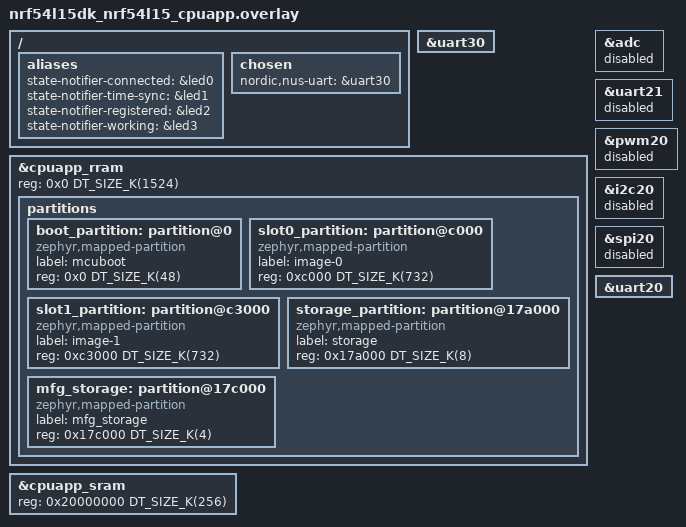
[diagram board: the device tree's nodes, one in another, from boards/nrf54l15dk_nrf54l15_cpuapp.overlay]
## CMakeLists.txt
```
#
# Copyright (c) 2023 Nordic Semiconductor ASA
#
# SPDX-License-Identifier: LicenseRef-Nordic-5-Clause
#

cmake_minimum_required(VERSION 3.20.0)

# Zephyr CMake project
find_package(Zephyr REQUIRED HINTS $ENV{ZEPHYR_BASE})
project(sidewalk_nus)

# Source files
target_include_directories(app PRIVATE include)
target_sources(app PRIVATE
src/main.c
src/sidewalk.c
src/sidewalk_events.c
)

target_sources_ifdef(CONFIG_SIDEWALK_FILE_TRANSFER app PRIVATE 
    src/sbdt/scratch_buffer.c
)
target_sources_ifdef(CONFIG_SIDEWALK_FILE_TRANSFER_DFU app PRIVATE
    src/sbdt/dfu_file_transfer.c
)

if(CONFIG_SID_END_DEVICE_SENSOR_MONITORING)
    target_sources(app PRIVATE
        src/sensor_monitoring/app_buttons.c
        src/sensor_monitoring/app_leds.c
        src/sensor_monitoring/app_sensor.c
        src/sensor_monitoring/app_tx.c
        src/sensor_monitoring/app_rx.c
        src/sensor_monitoring/app.c
    )
elseif(CONFIG_SID_END_DEVICE_DUT)
    target_sources(app PRIVATE
        src/cli/app.c
    )
else()
    target_sources(app PRIVATE
        src/hello/app.c
    )
endif()

target_sources_ifdef(CONFIG_SID_END_DEVICE_NUS_BRIDGE app PRIVATE
    src/nus_bridge/nus_bridge.c
)

if(CONFIG_SID_END_DEVICE_CLI)
    target_sources(app PRIVATE
        src/cli/app_dut.c
        src/cli/app_shell.c
    )
    target_sources_ifdef(CONFIG_SIDEWALK_FILE_TRANSFER_SHELL app PRIVATE
        src/cli/sbdt_shell.c
        src/cli/sbdt_shell_events.c
        src/cli/sbdt_shell_file_transfer.c
    )
    target_sources_ifdef(CONFIG_SIDEWALK_ON_DEV_CERT app PRIVATE 
        src/cli/sid_on_dev_cert_cli.c
    )
    target_sources_ifdef(CONFIG_SIDEWALK_LOCATION_SHELL app PRIVATE
        src/cli/location_shell.c
        src/cli/location_shell_events.c
    )
endif()

if(CONFIG_SIDEWALK_USE_PREBUILT_LIBRARIES)
    target_link_libraries(app PRIVATE sidewalk)
endif()
```

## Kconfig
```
#
# Copyright (c) 2022 Nordic Semiconductor ASA
#
# SPDX-License-Identifier: LicenseRef-Nordic-5-Clause
#

mainmenu "Sidewalk End Device nRF Connect Application"

choice SID_END_DEVICE
	prompt "Select application variant to run"
	default SID_END_DEVICE_HELLO
config SID_END_DEVICE_HELLO
	bool "Sidewalk hello world application"
config SID_END_DEVICE_SENSOR_MONITORING
	bool "Demo sensor monitoring application"
	imply SIDEWALK_DEMO_PARSER
	imply SENSOR
	imply TEMP_NRF5
config SID_END_DEVICE_DUT
	bool "Device under test application"
endchoice #SID_END_DEVICE

if SID_END_DEVICE_HELLO

config SID_END_DEVICE_ECHO_MSGS
	bool "Enable message echo feature"
	default y
	help
	  Echo received messages back to Sidewalk cloud.
	  Works with GET and SET messages types.

config SID_END_DEVICE_NUS_BRIDGE
	bool "Bridge Nordic UART Service to Sidewalk"
	select BT_NUS
	select SERIAL
	select UART_INTERRUPT_DRIVEN
	select RING_BUFFER
	help
	  Advertise the Nordic UART Service on the default BT identity next to Sidewalk.
	  The NUS peer can only send the commands !status, !mtu, !ping and !help,
	  answered over NUS; any other input is ignored and answered with the list of
	  commands. Sidewalk downlinks are notified to the NUS peer. Lines received on
	  the nordic,nus-uart UART are sent to the NUS peer, and all NUS traffic is
	  mirrored to that UART.

if SID_END_DEVICE_NUS_BRIDGE

config SID_END_DEVICE_NUS_BLE_NAME
	string "NUS advertising name"
	default "Sidewalk_NUS"

config SID_END_DEVICE_NUS_UART_LINE_MAX
	int "Max length of a UART line sent over NUS"
	default 128

endif # SID_END_DEVICE_NUS_BRIDGE

endif #SID_END_DEVICE_HELLO

# One more connection and advertising set for NUS. The Sidewalk add-on sets the
# same symbols, but defaults from the application Kconfig take precedence.
config BT_MAX_CONN
	default 3 if SID_END_DEVICE_NUS_BRIDGE && SIDEWALK_DFU
	default 2 if SID_END_DEVICE_NUS_BRIDGE

config BT_EXT_ADV_MAX_ADV_SET
	default 3 if SID_END_DEVICE_NUS_BRIDGE && SIDEWALK_DFU
	default 2 if SID_END_DEVICE_NUS_BRIDGE

if SID_END_DEVICE_SENSOR_MONITORING

rsource "Kconfig.sensor_monitoring"

endif #SID_END_DEVICE_SENSOR_MONITORING

config SID_END_DEVICE_CLI
	bool "Sidewalk CLI (DUT)"
	imply SHELL
	help
	  Enables Sidewalk command line interface.
	  The interface commands are compatible with former dut sample.

if SID_END_DEVICE_CLI

config SHELL_CMD_BUFF_SIZE
	default 1024

config SHELL_STACK_SIZE
	default 8192

config SHELL_BACKEND_SERIAL_TX_RING_BUFFER_SIZE
	default 128

config SHELL_BACKEND_SERIAL_RX_RING_BUFFER_SIZE
	default 1024

config SID_END_DEVICE_CLI_ALIVE_MARKER
	bool "Alive marker"
	help
	    Enable alive marker that periodically prints "alive" message to log.
	    Useful to verify that application is running and not stuck.

endif # SID_END_DEVICE_CLI

config SID_END_DEVICE_AUTO_START
	default y
	bool "Automatic Sidewalk initialization and start"

config SID_END_DEVICE_AUTO_CONN_REQ
	default y
	bool "Automatic connection request before message send"

config SID_END_DEVICE_PERSISTENT_LINK_MASK
	bool "Persistent link mask"
	help
	  The Sidewalk link mask persists after a device reset
	  but defaults after a factory reset.
	  This could affect the flash lifespan.

choice SID_END_DEVICE_LINK_MASK
	prompt "Physical link type"
	default SID_END_DEVICE_LINK_MASK_FSK if SIDEWALK_LINK_MASK_FSK
	default SID_END_DEVICE_LINK_MASK_LORA if SIDEWALK_LINK_MASK_LORA
	default SID_END_DEVICE_LINK_MASK_BLE if SIDEWALK_LINK_MASK_BLE
	default SID_END_DEVICE_LINK_MASK_BLE
	help
	  Choose the default physical link type for Sidewalk connection.

config SID_END_DEVICE_LINK_MASK_BLE
	bool "Bluetooth Low Energy link"

config SID_END_DEVICE_LINK_MASK_FSK
	bool "Sub-GHz link for FSK"

config SID_END_DEVICE_LINK_MASK_LORA
	bool "Sub-GHz link for LORA"

endchoice # SID_END_DEVICE_LINK_MASK

config SID_END_DEVICE_EVENT_HEAP_SIZE
	int "Heap for Sidewalk event contexts"
	default 2048

config SIDEWALK_FILE_TRANSFER
	select EXPERIMENTAL
	bool "Sidewalk file transfer [EXPERIMENTAL]"
	help
	  Add support for Sidewalk Bulk Data Transfer (SBDT)
	  in application.

if SIDEWALK_FILE_TRANSFER

config SIDEWALK_FILE_TRANSFER_HEAP_SIZE
	int "Sidewalk file transfer heap size"
	default 10240
	help
	    Heap size in bytes to be allocated
	    for Sidewalk Bulk Data Transfer (SBDT).

choice SIDEWALK_FILE_TRANSFER_IMPL
	prompt "Select which implementation of SBDT to use"
	default SIDEWALK_FILE_TRANSFER_DFU

config SIDEWALK_FILE_TRANSFER_DFU
	bool "Sidewalk file transfer and dfu"
	imply SIDEWALK_DFU_IMG_UTILS
	imply DFU_MULTI_IMAGE
	imply DFU_TARGET
	imply DFU_TARGET_MCUBOOT
	imply STREAM_FLASH
	imply STREAM_FLASH_ERASE
	help
	    Save received data to flash. Expect CBOR manifest.
	    Automatically reset device after file transfer.

config SIDEWALK_FILE_TRANSFER_SHELL
	bool "SBDT cli backend for file transfer"
	imply SHELL
	help
	    Use shell commands to control file transfer.
	    This implementation does not save received data,
	    but allows user to control the sbdt behaviour from shell.

endchoice

config SBDT_MAX_PARALLEL_TRANSFERS
	int "maximum number of sbdt parallel transfers"
	default 3

endif # SIDEWALK_FILE_TRANSFER

config SIDEWALK_LOCATION_SHELL
	bool "Sidewalk Location CLI"
	depends on SID_END_DEVICE_CLI
	help
	    Enables Sidewalk location and dult command line interface.
	    Provides commands for location services and unwanted location tracking.

if SIDEWALK_CRYPTO

choice CC3XX_LOCK_VARIANT
	default CC3XX_ATOMIC_LOCK if SOC_NRF52840
endchoice

config PSA_WANT_ALG_SHA_512
	default y if SOC_SERIES_NRF54LX

config PSA_WANT_ALG_CHACHA20_POLY1305
	default n

config PSA_WANT_ALG_SHA_224
	default n

config PSA_WANT_ALG_SHA_384
	default n

config PSA_WANT_ALG_CBC_NO_PADDING
	default n

config PSA_WANT_ALG_CBC_PKCS7
	default n

config PSA_WANT_ALG_HKDF
	default n

config PSA_USE_CC3XX_KEY_AGREEMENT_DRIVER
	default n if SOC_NRF52840

config PSA_USE_CC3XX_ASYMMETRIC_SIGNATURE_DRIVER
	default n if SOC_NRF52840

config PSA_USE_CC3XX_ASYMMETRIC_ENCRYPTION_DRIVER
	default n if SOC_NRF52840

config PSA_USE_CC3XX_KEY_MANAGEMENT_DRIVER
	default n if SOC_NRF52840

endif #SIDEWALK_CRYPTO

if SHELL
# TODO: Remove when merged in NCS copy of sdk-zephyr https://github.com/zephyrproject-rtos/zephyr/pull/85790
# Workaround for missing first few logs.
config LOG_BACKEND_RTT
	bool "Segger J-Link RTT backend"
	depends on USE_SEGGER_RTT
	default y if !SHELL_LOG_BACKEND
	default n
endif #SHELL



source "Kconfig.zephyr"
```

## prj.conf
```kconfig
#
# Copyright (c) 2023 Nordic Semiconductor ASA
#
# SPDX-License-Identifier: LicenseRef-Nordic-5-Clause
#
CONFIG_STATIC_INIT_GNU=y

# Sidewalk
CONFIG_SIDEWALK=y
CONFIG_SMF=y

# NUS <-> Sidewalk bridge (downlinks go to NUS instead of being echoed)
CONFIG_SID_END_DEVICE_NUS_BRIDGE=y
CONFIG_SID_END_DEVICE_ECHO_MSGS=n
CONFIG_BT_DEVICE_NAME="Sidewalk_NUS"

# Log
CONFIG_LOG=y
CONFIG_LOG_PRINTK=y
CONFIG_LOG_BUFFER_SIZE=4096

# Stack and Heap
CONFIG_SYSTEM_WORKQUEUE_STACK_SIZE=4096
CONFIG_HEAP_MEM_POOL_SIZE=4096
CONFIG_MBEDTLS_HEAP_SIZE=4096

# Power Management
CONFIG_PM_DEVICE=y

# Debug
CONFIG_NCS_APPLICATION_BOOT_BANNER_STRING="Sidewalk"
CONFIG_RESET_ON_FATAL_ERROR=n
CONFIG_SYS_HEAP_RUNTIME_STATS=y
```

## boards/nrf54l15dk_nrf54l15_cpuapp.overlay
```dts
/*
 * Copyright (c) 2024 Nordic Semiconductor ASA
 *
 * SPDX-License-Identifier: LicenseRef-Nordic-5-Clause
 */

/{
	aliases {
		state-notifier-connected = &led0;
		state-notifier-time-sync = &led1;
		state-notifier-registered = &led2;
		state-notifier-working = &led3;
	};

	chosen {
		/* NUS UART on the second DK VCOM, the console stays on uart20. */
		nordic,nus-uart = &uart30;
	};
};

&uart30 {
	status = "okay";
};

&cpuapp_rram {
	reg = <0x0 DT_SIZE_K(1524)>;
};

&cpuapp_sram {
	reg = <0x20000000 DT_SIZE_K(256)>;
	ranges = <0x0 0x20000000  0x40000>;
};

&adc {
	status = "disabled";
};
&uart21 {
	status = "disabled";
};
&pwm20 {
	status = "disabled";
};
&i2c20 {
	status = "disabled";
};
&spi20 {
	status = "disabled";
};

// TODO: re-enable HWFC once it's fixed
&uart20 {
	/delete-property/ hw-flow-control;
};

/delete-node/ &boot_partition;
/delete-node/ &slot0_partition;
/delete-node/ &slot1_partition;
/delete-node/ &storage_partition;

&cpuapp_rram {
	partitions {
		ranges;
		#address-cells = <1>;
		#size-cells = <1>;

		boot_partition: partition@0 {
			compatible = "zephyr,mapped-partition";
			label = "mcuboot";
			reg = <0x0 DT_SIZE_K(48)>;
		};

		slot0_partition: partition@c000 {
			compatible = "zephyr,mapped-partition";
			label = "image-0";
			reg = <0xc000 DT_SIZE_K(732)>;
		};

		slot1_partition: partition@c3000 {
			compatible = "zephyr,mapped-partition";
			label = "image-1";
			reg = <0xc3000 DT_SIZE_K(732)>;
		};

		storage_partition: partition@17a000 {
			compatible = "zephyr,mapped-partition";
			label = "storage";
			reg = <0x17a000 DT_SIZE_K(8)>;
		};

		mfg_storage: partition@17c000 {
			compatible = "zephyr,mapped-partition";
			label = "mfg_storage";
			reg = <0x17c000 DT_SIZE_K(4)>;
		};
	};
};
```

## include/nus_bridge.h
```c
/*
 * Copyright (c) 2026 Nordic Semiconductor ASA
 *
 * SPDX-License-Identifier: LicenseRef-Nordic-5-Clause
 */
#ifndef NUS_BRIDGE_H
#define NUS_BRIDGE_H

#include <stdbool.h>
#include <stddef.h>
#include <stdint.h>
#include <zephyr/bluetooth/bluetooth.h>
#include <zephyr/bluetooth/gatt.h>
#include <sid_api.h>

/**
 * @brief BT identity used by the NUS link.
 * Sidewalk uses BT_ID_SIDEWALK (and BT_ID_SMP_DFU with DFU), the default identity is free.
 */
#define NUS_BRIDGE_BT_ID BT_ID_DEFAULT

/**
 * @brief Enable BT, start NUS advertising and the NUS UART.
 * Must be called from the Sidewalk event thread, because sid_ble_bt_enable is not thread safe.
 *
 * @return 0 on success, negative errno otherwise
 */
int nus_bridge_start(void);

/**
 * @brief Sidewalk on_msg_received hook.
 * Completes a pending !ping on its ack, forwards other downlinks to the NUS peer and the NUS UART.
 * Call from the Sidewalk thread.
 *
 * @param msg_desc message descriptor
 * @param msg message
 */
void nus_bridge_sid_msg_received(const struct sid_msg_desc *msg_desc, const struct sid_msg *msg);

/**
 * @brief Sidewalk on_msg_sent hook, reports !ping progress. Call from the Sidewalk thread.
 *
 * @param msg_desc message descriptor
 */
void nus_bridge_sid_msg_sent(const struct sid_msg_desc *msg_desc);

/**
 * @brief Sidewalk on_send_error hook, reports a failed !ping. Call from the Sidewalk thread.
 *
 * @param error send error
 * @param msg_desc message descriptor
 */
void nus_bridge_sid_send_error(sid_error_t error, const struct sid_msg_desc *msg_desc);

/**
 * @brief check if attr is a NUS characteristic value
 *
 * @param attr
 * @return true if attr belongs to NUS
 * @return false in other cases
 */
bool nus_bridge_attr_is_NUS(const struct bt_gatt_attr *attr);

#endif /* NUS_BRIDGE_H */
```

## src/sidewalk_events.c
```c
/*
 * Copyright (c) 2024 Nordic Semiconductor ASA
 *
 * SPDX-License-Identifier: LicenseRef-Nordic-5-Clause
 */

#include "json_printer/sidTypes2str.h"
#include <sidewalk.h>
#include <sid_error.h>
#include <app_mfg_config.h>
#include <sid_pal_common_ifc.h>
#include <sid_hal_memory_ifc.h>
#ifdef CONFIG_SIDEWALK_SUBGHZ_SUPPORT
#include <app_subGHz_config.h>
#include <sid_pal_radio_ifc.h>
#ifdef CONFIG_SIDEWALK_SUBGHZ_RADIO_LR1110
#include <app_location_lr11xx_config.h>
#endif /* CONFIG_SIDEWALK_SUBGHZ_RADIO_LR1110 */
#endif /* CONFIG_SIDEWALK_SUBGHZ_SUPPORT */

#include <zephyr/logging/log.h>
#include <zephyr/logging/log_ctrl.h>
#include <zephyr/sys/reboot.h>
#include <json_printer/sidTypes2Json.h>
#include <sidewalk_dfu/nordic_dfu.h>
#ifdef CONFIG_SID_END_DEVICE_PERSISTENT_LINK_MASK
#include <settings_utils.h>
#endif /* CONFIG_SID_END_DEVICE_PERSISTENT_LINK_MASK */

#ifdef CONFIG_SIDEWALK_FILE_TRANSFER_DFU
#include <sbdt/dfu_file_transfer.h>
#include <zephyr/dfu/mcuboot.h>
#endif /* CONFIG_SIDEWALK_FILE_TRANSFER_DFU */

LOG_MODULE_REGISTER(sidewalk_events, CONFIG_SIDEWALK_LOG_LEVEL);

#define SIDEWALK_PROVISIONING_DOC_URL                                                              \
	"https://nrfconnectdocs.nordicsemi.com/addons/addon-sidewalk/latest/"                      \
	"setting_up_sidewalk_environment/setting_up_sidewalk_prototype.html"

#ifdef CONFIG_SIDEWALK_SUBGHZ_SUPPORT
static sid_pal_radio_rx_packet_t radio_rx_packet;

static void radio_event_notifier(sid_pal_radio_events_t event)
{
	LOG_DBG("Radio event %d", event);
}

static void radio_irq_handler(void)
{
	LOG_DBG("Radio IRQ");
}
#endif /* CONFIG_SIDEWALK_SUBGHZ_SUPPORT */

// private
void sidewalk_event_process(sidewalk_ctx_t *sid, void *ctx)
{
	if (sid == NULL || sid->handle == NULL) {
		LOG_INF("sidewalk need to be started first.");
		return;
	}
	sid_error_t e = sid_process(sid->handle);

	if (e) {
		LOG_ERR("sid process err  %d (%s)", (int)e, SID_ERROR_T_STR(e));
	}
}

void sidewalk_event_platform_init(sidewalk_ctx_t *sid, void *ctx)
{
	platform_parameters_t platform_parameters = {
		.mfg_store_region.addr_start = APP_MFG_CFG_FLASH_START,
		.mfg_store_region.addr_end = APP_MFG_CFG_FLASH_END,
#ifdef CONFIG_SIDEWALK_SUBGHZ_SUPPORT
		.platform_init_parameters.radio_cfg = get_radio_cfg(),
#ifdef CONFIG_SIDEWALK_SUBGHZ_RADIO_LR1110
		.platform_init_parameters.gnss_wifi_cfg =
			(lr11xx_gnss_wifi_config_t *)get_location_cfg(),
#endif /* CONFIG_SIDEWALK_SUBGHZ_RADIO_LR1110 */
#endif /* CONFIG_SIDEWALK_SUBGHZ_SUPPORT */
	};

	sid_error_t e = sid_platform_init(&platform_parameters);

	if (e != SID_ERROR_NONE) {
		LOG_ERR("Sidewalk Platform Init err:  %d (%s)", (int)e, SID_ERROR_T_STR(e));
		return;
	}
	if (app_mfg_cfg_is_empty()) {
		LOG_ERR("The mfg.hex version mismatch");
		LOG_ERR("Check if the file has been generated and flashed properly");
		LOG_ERR("START ADDRESS: 0x%08x", APP_MFG_CFG_FLASH_START);
		LOG_ERR("SIZE: 0x%08x", APP_MFG_CFG_FLASH_SIZE);
		LOG_ERR("To provision the device, follow: %s", SIDEWALK_PROVISIONING_DOC_URL);
		return;
	}

#ifdef CONFIG_SIDEWALK_SUBGHZ_SUPPORT
	int32_t err = sid_pal_radio_init(radio_event_notifier, radio_irq_handler, &radio_rx_packet);

	if (err) {
		LOG_ERR("radio init err %d", err);
		return;
	}
	err = sid_pal_radio_sleep(0);
	if (err) {
		LOG_ERR("radio sleep err %d", err);
	}
#endif /* CONFIG_SIDEWALK_SUBGHZ_SUPPORT */
}

void sidewalk_event_autostart(sidewalk_ctx_t *sid, void *ctx)
{
	if (sid->handle != NULL) {
		LOG_INF("Sidewalk is already running");
		return;
	}
	if (app_mfg_cfg_is_empty()) {
		LOG_ERR("The mfg.hex version mismatch");
		LOG_ERR("Check if the file has been generated and flashed properly");
		LOG_ERR("START ADDRESS: 0x%08x", APP_MFG_CFG_FLASH_START);
		LOG_ERR("SIZE: 0x%08x", APP_MFG_CFG_FLASH_SIZE);
		LOG_ERR("To provision the device, follow: %s", SIDEWALK_PROVISIONING_DOC_URL);
		return;
	}
#ifdef CONFIG_SID_END_DEVICE_PERSISTENT_LINK_MASK
	int err = settings_utils_link_mask_get(&sid->config.link_mask);

	if (err <= 0) {
		LOG_WRN("Link mask get failed %d", err);
		sid->config.link_mask = 0;
		settings_utils_link_mask_set(DEFAULT_LM);
	}
#endif /* CONFIG_SID_END_DEVICE_PERSISTENT_LINK_MASK */

	if (!sid->config.link_mask) {
		sid->config.link_mask = DEFAULT_LM;
	}

	LOG_INF("Sidewalk link switch to %s", (SID_LINK_TYPE_3 & sid->config.link_mask) ? "LoRa" :
					      (SID_LINK_TYPE_2 & sid->config.link_mask) ? "FSK" :
											  "BLE");
	sid_error_t e = sid_init(&sid->config, &sid->handle);

	if (e) {
		LOG_ERR("sid init err %d (%s)", (int)e, SID_ERROR_T_STR(e));
		return;
	}

	e = sid_start(sid->handle, sid->config.link_mask);
	if (e) {
		LOG_ERR("sid start err %d (%s)", (int)e, SID_ERROR_T_STR(e));
	}

#if CONFIG_SID_END_DEVICE_AUTO_CONN_REQ
	if (sid->config.link_mask & SID_LINK_TYPE_1) {
		enum sid_link_connection_policy set_policy =
			SID_LINK_CONNECTION_POLICY_AUTO_CONNECT;

		e = sid_option(sid->handle, SID_OPTION_SET_LINK_CONNECTION_POLICY, &set_policy,
			       sizeof(set_policy));
		if (e) {
			LOG_ERR("sid option multi link manager err %d", (int)e);
		}

		struct sid_link_auto_connect_params ac_params = {
			.link_type = SID_LINK_TYPE_1,
			.enable = true,
			.priority = 0,
			.connection_attempt_timeout_seconds = 30
		};

		e = sid_option(sid->handle, SID_OPTION_SET_LINK_POLICY_AUTO_CONNECT_PARAMS,
			       &ac_params, sizeof(ac_params));
		if (e) {
			LOG_ERR("sid option multi link policy err %d", (int)e);
		}
	}
#endif /* CONFIG_SID_END_DEVICE_AUTO_CONN_REQ */
#ifdef CONFIG_SIDEWALK_FILE_TRANSFER_DFU
	int dfu_err = boot_write_img_confirmed();

	if (dfu_err) {
		LOG_ERR("img confirm fail %d", dfu_err);
	}
	app_file_transfer_demo_init(sid->handle);
#endif /* CONFIG_SIDEWALK_FILE_TRANSFER_DFU */
}

void sidewalk_event_factory_reset(sidewalk_ctx_t *sid, void *ctx)
{
	if (sid == NULL || sid->handle == NULL) {
		LOG_INF("sidewalk need to be started first.");
		return;
	}
#ifdef CONFIG_SID_END_DEVICE_PERSISTENT_LINK_MASK
	(void)settings_utils_link_mask_set(0);
#endif /* CONFIG_SID_END_DEVICE_PERSISTENT_LINK_MASK */
	sid_error_t e = sid_set_factory_reset(sid->handle);

	if (e) {
		LOG_ERR("sid factory reset err  %d (%s)", (int)e, SID_ERROR_T_STR(e));
	}
}

void sidewalk_event_new_status(sidewalk_ctx_t *sid, void *ctx)
{
	struct sid_status *p_status = (struct sid_status *)ctx;

	if (!p_status) {
		LOG_ERR("sid new status is NULL");
		return;
	}

	memcpy(&sid->last_status, p_status, sizeof(struct sid_status));
}
void sidewalk_event_send_msg(sidewalk_ctx_t *sid, void *ctx)
{
	if (sid == NULL || sid->handle == NULL) {
		LOG_INF("sidewalk need to be started first.");
		return;
	}
	sidewalk_msg_t *p_msg = (sidewalk_msg_t *)ctx;

	if (!p_msg) {
		LOG_ERR("sid send msg is NULL");
		return;
	}

	sid_error_t e = sid_put_msg(sid->handle, &p_msg->msg, &p_msg->desc);

	if (e) {
		LOG_ERR("sid send err %d", (int)e);
		return;
	}
	LOG_DBG("sid send (type: %d, id: %u)", (int)p_msg->desc.type, p_msg->desc.id);
}
void sidewalk_event_connect(sidewalk_ctx_t *sid, void *ctx)
{
	if (sid == NULL || sid->handle == NULL) {
		LOG_INF("sidewalk need to be started first.");
		return;
	}
	if (!(sid->config.link_mask & SID_LINK_TYPE_1)) {
		LOG_ERR("Can not request connection - BLE not enabled");
		return;
	}
	sid_error_t e = sid_ble_bcn_connection_request(sid->handle, true);

	if (e) {
		LOG_ERR("sid conn req err %d (%s)", (int)e, SID_ERROR_T_STR(e));
	}
}
void sidewalk_event_link_switch(sidewalk_ctx_t *sid, void *ctx)
{
	if (sid == NULL || sid->handle == NULL) {
		LOG_INF("Can not change link if sidewalk was not started yet");
		return;
	}
	static uint32_t new_link_mask = DEFAULT_LM;

	switch (sid->config.link_mask) {
	case SID_LINK_TYPE_1:
		new_link_mask = SID_LINK_TYPE_2;
		break;
	case SID_LINK_TYPE_2:
		new_link_mask = SID_LINK_TYPE_1 | SID_LINK_TYPE_3;
		break;
	default:
		new_link_mask = SID_LINK_TYPE_1;
		break;
	}
	sid->config.link_mask = new_link_mask;

	LOG_INF("Sidewalk link switch to %s", (SID_LINK_TYPE_3 & new_link_mask) ? "LoRa" :
					      (SID_LINK_TYPE_2 & new_link_mask) ? "FSK" :
										  "BLE");
#ifdef CONFIG_SID_END_DEVICE_PERSISTENT_LINK_MASK
	int err = settings_utils_link_mask_set(new_link_mask);

	if (err) {
		LOG_ERR("New link mask set err %d", err);
	}
#endif /* CONFIG_SID_END_DEVICE_PERSISTENT_LINK_MASK */

	if (sid->handle != NULL) {
#ifdef CONFIG_SIDEWALK_FILE_TRANSFER_DFU
		app_file_transfer_demo_deinit(sid->handle);
#endif
		(void)sid_process(sid->handle);
		sid_error_t e = sid_deinit(sid->handle);

		if (e) {
			LOG_ERR("sid deinit err %d (%s)", (int)e, SID_ERROR_T_STR(e));
		}
	}

	sid_error_t e = sid_init(&sid->config, &sid->handle);

	if (e) {
		LOG_ERR("sid init err %d (%s)", (int)e, SID_ERROR_T_STR(e));
	}
#ifdef CONFIG_SIDEWALK_FILE_TRANSFER_DFU
	app_file_transfer_demo_init(sid->handle);
#endif
	e = sid_start(sid->handle, sid->config.link_mask);
	if (e) {
		LOG_ERR("sid start err %d (%s)", (int)e, SID_ERROR_T_STR(e));
	}
#if CONFIG_SID_END_DEVICE_AUTO_CONN_REQ
	if (sid->config.link_mask & SID_LINK_TYPE_1) {
		enum sid_link_connection_policy set_policy =
			SID_LINK_CONNECTION_POLICY_AUTO_CONNECT;

		e = sid_option(sid->handle, SID_OPTION_SET_LINK_CONNECTION_POLICY, &set_policy,
			       sizeof(set_policy));
		if (e) {
			LOG_ERR("sid option multi link manager err %d (%s)", (int)e,
				SID_ERROR_T_STR(e));
		}

		struct sid_link_auto_connect_params ac_params = {
			.link_type = SID_LINK_TYPE_1,
			.enable = true,
			.priority = 0,
			.connection_attempt_timeout_seconds = 30
		};

		e = sid_option(sid->handle, SID_OPTION_SET_LINK_POLICY_AUTO_CONNECT_PARAMS,
			       &ac_params, sizeof(ac_params));
		if (e) {
			LOG_ERR("sid option multi link policy err %d (%s)", (int)e,
				SID_ERROR_T_STR(e));
		}
	}
#endif /* CONFIG_SID_END_DEVICE_AUTO_CONN_REQ */
}

void sidewalk_event_exit(sidewalk_ctx_t *sid, void *ctx)
{
	if (sid == NULL || sid->handle == NULL) {
		LOG_INF("Sidewalk is already deinitialized");
		return;
	}
#ifdef CONFIG_SIDEWALK_FILE_TRANSFER_DFU
	app_file_transfer_demo_deinit(sid->handle);
#endif
	(void)sid_process(sid->handle);
	(void)sid_deinit(sid->handle);
}

void sidewalk_event_reboot(sidewalk_ctx_t *sid, void *ctx)
{
	LOG_INF("Rebooting...");
	LOG_PANIC();
	sys_reboot(SYS_REBOOT_WARM);
}
```
